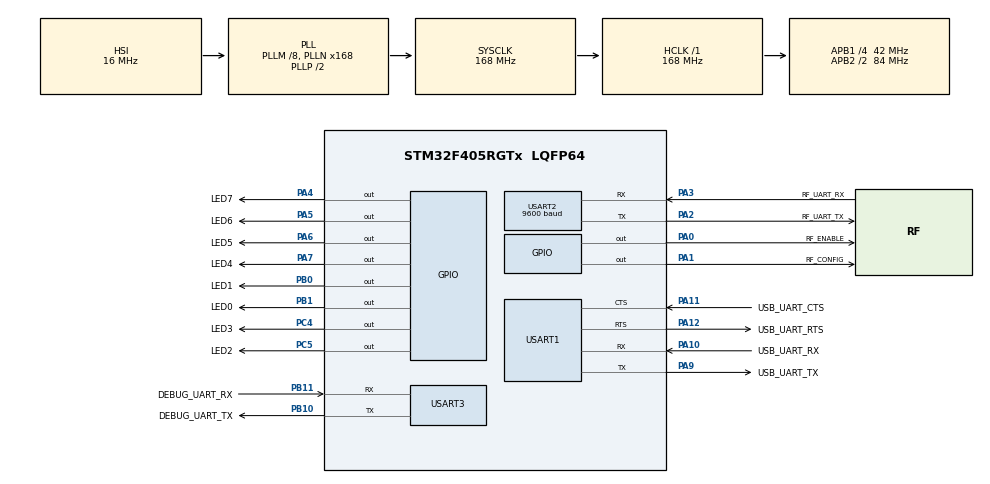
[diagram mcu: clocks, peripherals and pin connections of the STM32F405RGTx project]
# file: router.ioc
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Mcu.Family=STM32F4
Mcu.Name=STM32F405RGTx
Mcu.Package=LQFP64
NVIC.PriorityGroup=NVIC_PRIORITYGROUP_4
NVIC.USART1_IRQn=true\:0\:0\:false\:false\:true\:true
NVIC.USART2_IRQn=true\:0\:0\:false\:false\:true\:true
NVIC.USART3_IRQn=true\:0\:0\:false\:false\:true\:true
PA0-WKUP.GPIO_Label=RF_ENABLE
PA0-WKUP.Signal=GPIO_Output
PA1.GPIO_Label=RF_CONFIG
PA1.Signal=GPIO_Output
PA10.GPIO_Label=USB_UART_RX
PA10.Mode=Asynchronous
PA10.Signal=USART1_RX
PA11.GPIO_Label=USB_UART_CTS
PA11.Mode=CTS_RTS
PA11.Signal=USART1_CTS
PA12.GPIO_Label=USB_UART_RTS
PA12.Mode=CTS_RTS
PA12.Signal=USART1_RTS
PA13.Mode=Serial_Wire
PA13.Signal=SYS_JTMS-SWDIO
PA14.Mode=Serial_Wire
PA14.Signal=SYS_JTCK-SWCLK
PA2.GPIO_Label=RF_UART_TX
PA2.Mode=Asynchronous
PA2.Signal=USART2_TX
PA3.GPIO_Label=RF_UART_RX
PA3.Mode=Asynchronous
PA3.Signal=USART2_RX
PA4.GPIO_Label=LED7
PA4.Signal=GPIO_Output
PA5.GPIO_Label=LED6
PA5.Signal=GPIO_Output
PA6.GPIO_Label=LED5
PA6.Signal=GPIO_Output
PA7.GPIO_Label=LED4
PA7.Signal=GPIO_Output
PA9.GPIO_Label=USB_UART_TX
PA9.Mode=Asynchronous
PA9.Signal=USART1_TX
PB0.GPIO_Label=LED1
PB0.Signal=GPIO_Output
PB1.GPIO_Label=LED0
PB1.Signal=GPIO_Output
PB10.GPIO_Label=DEBUG_UART_TX
PB10.Mode=Asynchronous
PB10.Signal=USART3_TX
PB11.GPIO_Label=DEBUG_UART_RX
PB11.Mode=Asynchronous
PB11.Signal=USART3_RX
PC14-OSC32_IN.Mode=LSE-External-Oscillator
PC14-OSC32_IN.Signal=RCC_OSC32_IN
PC15-OSC32_OUT.Mode=LSE-External-Oscillator
PC15-OSC32_OUT.Signal=RCC_OSC32_OUT
PC4.GPIO_Label=LED3
PC4.Signal=GPIO_Output
PC5.GPIO_Label=LED2
PC5.Signal=GPIO_Output
ProjectManager.HeapSize=0x200
ProjectManager.StackSize=0x400
ProjectManager.TargetToolchain=Makefile
RCC.48MHZClocksFreq_Value=84000000
RCC.AHBFreq_Value=168000000
RCC.APB1CLKDivider=RCC_HCLK_DIV4
RCC.APB1Freq_Value=42000000
RCC.APB1TimFreq_Value=84000000
RCC.APB2CLKDivider=RCC_HCLK_DIV2
RCC.APB2Freq_Value=84000000
RCC.APB2TimFreq_Value=168000000
RCC.CortexFreq_Value=168000000
RCC.HCLKFreq_Value=168000000
RCC.HSE_VALUE=25000000
RCC.HSI_VALUE=16000000
RCC.PLLM=8
RCC.PLLN=168
RCC.RCC_RTC_Clock_Source=RCC_RTCCLKSOURCE_LSE
RCC.RCC_RTC_Clock_SourceVirtual=RCC_RTCCLKSOURCE_LSE
RCC.SYSCLKFreq_VALUE=168000000
RCC.SYSCLKSource=RCC_SYSCLKSOURCE_PLLCLK
RCC.VCOOutputFreq_Value=336000000
USART1.VirtualMode=VM_ASYNC
USART2.BaudRate=9600
USART2.VirtualMode=VM_ASYNC
USART3.VirtualMode=VM_ASYNC
VP_RTC_VS_RTC_Activate.Mode=RTC_Enabled
board=router

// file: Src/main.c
/**
 ******************************************************************************
 * @file           : main.c
 * @brief          : Main program body
 ******************************************************************************
 ** This notice applies to any and all portions of this file
 * that are not between comment pairs USER CODE BEGIN and
 * USER CODE END. Other portions of this file, whether
 * inserted by the user or by software development tools
 * are owned by their respective copyright owners.
 *
 * COPYRIGHT(c) 2018 STMicroelectronics
 *
 * Redistribution and use in source and binary forms, with or without modification,
 * are permitted provided that the following conditions are met:
 *   1. Redistributions of source code must retain the above copyright notice,
 *      this list of conditions and the following disclaimer.
 *   2. Redistributions in binary form must reproduce the above copyright notice,
 *      this list of conditions and the following disclaimer in the documentation
 *      and/or other materials provided with the distribution.
 *   3. Neither the name of STMicroelectronics nor the names of its contributors
 *      may be used to endorse or promote products derived from this software
 *      without specific prior written permission.
 *
 * THIS SOFTWARE IS PROVIDED BY THE COPYRIGHT HOLDERS AND CONTRIBUTORS "AS IS"
 * AND ANY EXPRESS OR IMPLIED WARRANTIES, INCLUDING, BUT NOT LIMITED TO, THE
 * IMPLIED WARRANTIES OF MERCHANTABILITY AND FITNESS FOR A PARTICULAR PURPOSE ARE
 * DISCLAIMED. IN NO EVENT SHALL THE COPYRIGHT HOLDER OR CONTRIBUTORS BE LIABLE
 * FOR ANY DIRECT, INDIRECT, INCIDENTAL, SPECIAL, EXEMPLARY, OR CONSEQUENTIAL
 * DAMAGES (INCLUDING, BUT NOT LIMITED TO, PROCUREMENT OF SUBSTITUTE GOODS OR
 * SERVICES; LOSS OF USE, DATA, OR PROFITS; OR BUSINESS INTERRUPTION) HOWEVER
 * CAUSED AND ON ANY THEORY OF LIABILITY, WHETHER IN CONTRACT, STRICT LIABILITY,
 * OR TORT (INCLUDING NEGLIGENCE OR OTHERWISE) ARISING IN ANY WAY OUT OF THE USE
 * OF THIS SOFTWARE, EVEN IF ADVISED OF THE POSSIBILITY OF SUCH DAMAGE.
 *
 ******************************************************************************
 */
#include "main.h"
#include "stm32f4xx_hal.h"

/* USER CODE BEGIN Includes */
#include "globals.hpp"
#include <string>
/* USER CODE END Includes */

RTC_HandleTypeDef hrtc;

UART_HandleTypeDef huart1;
UART_HandleTypeDef huart2;
UART_HandleTypeDef huart3;

/* USER CODE BEGIN PV */
/* Private variables ---------------------------------------------------------*/

/* USER CODE END PV */

void SystemClock_Config(void);
static void MX_GPIO_Init(void);
static void MX_USART1_UART_Init(void);
static void MX_USART2_UART_Init(void);
static void MX_USART3_UART_Init(void);
static void MX_RTC_Init(void);

/* USER CODE BEGIN PFP */
/* Private function prototypes -----------------------------------------------*/

/* USER CODE END PFP */

int main(void)
{

    /* MCU Configuration----------------------------------------------------------*/

    /* Reset of all peripherals, Initializes the Flash interface and the Systick. */
    HAL_Init();

    /* Configure the system clock */
    SystemClock_Config();

    /* Initialize all configured peripherals */
    MX_GPIO_Init();
    MX_USART1_UART_Init();
    MX_USART2_UART_Init();
    MX_USART3_UART_Init();
    MX_RTC_Init();
    /* USER CODE BEGIN 2 */
    global->usb   = new USB(&huart1);
    global->hmtrp = new HMTRP(&huart2, 57600, 0);
    global->radio_buffer_rx = new CircularBuffer;

    global->usb->tx("START\n");

    /* USER CODE END 2 */

    /* Infinite loop */
    while (1)
    {

        /* USER CODE BEGIN 3 */
        for (uint8_t i = 0; i < 10; i++)
        {
            HAL_Delay(500);
            //global->hmtrp->tx(i);
        }
    }
    /* USER CODE END 3 */
} /* main */

void SystemClock_Config(void)
{
    RCC_OscInitTypeDef RCC_OscInitStruct;
    RCC_ClkInitTypeDef RCC_ClkInitStruct;
    RCC_PeriphCLKInitTypeDef PeriphClkInitStruct;

    /**Configure the main internal regulator output voltage
     */
    __HAL_RCC_PWR_CLK_ENABLE();

    __HAL_PWR_VOLTAGESCALING_CONFIG(PWR_REGULATOR_VOLTAGE_SCALE1);

    /**Initializes the CPU, AHB and APB busses clocks
     */
    RCC_OscInitStruct.OscillatorType      = RCC_OSCILLATORTYPE_HSI | RCC_OSCILLATORTYPE_LSE;
    RCC_OscInitStruct.LSEState            = RCC_LSE_ON;
    RCC_OscInitStruct.HSIState            = RCC_HSI_ON;
    RCC_OscInitStruct.HSICalibrationValue = 16;
    RCC_OscInitStruct.PLL.PLLState        = RCC_PLL_ON;
    RCC_OscInitStruct.PLL.PLLSource       = RCC_PLLSOURCE_HSI;
    RCC_OscInitStruct.PLL.PLLM            = 8;
    RCC_OscInitStruct.PLL.PLLN            = 168;
    RCC_OscInitStruct.PLL.PLLP            = RCC_PLLP_DIV2;
    RCC_OscInitStruct.PLL.PLLQ            = 4;
    if (HAL_RCC_OscConfig(&RCC_OscInitStruct) != HAL_OK)
    {
        _Error_Handler(__FILE__, __LINE__);
    }

    /**Initializes the CPU, AHB and APB busses clocks
     */
    RCC_ClkInitStruct.ClockType = RCC_CLOCKTYPE_HCLK | RCC_CLOCKTYPE_SYSCLK
      | RCC_CLOCKTYPE_PCLK1 | RCC_CLOCKTYPE_PCLK2;
    RCC_ClkInitStruct.SYSCLKSource   = RCC_SYSCLKSOURCE_PLLCLK;
    RCC_ClkInitStruct.AHBCLKDivider  = RCC_SYSCLK_DIV1;
    RCC_ClkInitStruct.APB1CLKDivider = RCC_HCLK_DIV4;
    RCC_ClkInitStruct.APB2CLKDivider = RCC_HCLK_DIV2;

    if (HAL_RCC_ClockConfig(&RCC_ClkInitStruct, FLASH_LATENCY_5) != HAL_OK)
    {
        _Error_Handler(__FILE__, __LINE__);
    }

    PeriphClkInitStruct.PeriphClockSelection = RCC_PERIPHCLK_RTC;
    PeriphClkInitStruct.RTCClockSelection    = RCC_RTCCLKSOURCE_LSE;
    if (HAL_RCCEx_PeriphCLKConfig(&PeriphClkInitStruct) != HAL_OK)
    {
        _Error_Handler(__FILE__, __LINE__);
    }

    /**Configure the Systick interrupt time
     */
    HAL_SYSTICK_Config(HAL_RCC_GetHCLKFreq() / 1000);

    /**Configure the Systick
     */
    HAL_SYSTICK_CLKSourceConfig(SYSTICK_CLKSOURCE_HCLK);

    /* SysTick_IRQn interrupt configuration */
    HAL_NVIC_SetPriority(SysTick_IRQn, 0, 0);
} /* SystemClock_Config */

/* RTC init function */
static void MX_RTC_Init(void)
{
    /**Initialize RTC Only
     */
    hrtc.Instance            = RTC;
    hrtc.Init.HourFormat     = RTC_HOURFORMAT_24;
    hrtc.Init.AsynchPrediv   = 127;
    hrtc.Init.SynchPrediv    = 255;
    hrtc.Init.OutPut         = RTC_OUTPUT_DISABLE;
    hrtc.Init.OutPutPolarity = RTC_OUTPUT_POLARITY_HIGH;
    hrtc.Init.OutPutType     = RTC_OUTPUT_TYPE_OPENDRAIN;
    if (HAL_RTC_Init(&hrtc) != HAL_OK)
    {
        _Error_Handler(__FILE__, __LINE__);
    }
}

/* USART1 init function */
static void MX_USART1_UART_Init(void)
{
    huart1.Instance          = USART1;
    huart1.Init.BaudRate     = 115200;
    huart1.Init.WordLength   = UART_WORDLENGTH_8B;
    huart1.Init.StopBits     = UART_STOPBITS_1;
    huart1.Init.Parity       = UART_PARITY_NONE;
    huart1.Init.Mode         = UART_MODE_TX_RX;
    huart1.Init.HwFlowCtl    = UART_HWCONTROL_RTS_CTS;
    huart1.Init.OverSampling = UART_OVERSAMPLING_16;
    if (HAL_UART_Init(&huart1) != HAL_OK)
    {
        _Error_Handler(__FILE__, __LINE__);
    }
}

/* USART2 init function */
static void MX_USART2_UART_Init(void)
{
    huart2.Instance          = USART2;
    huart2.Init.BaudRate     = 9600;
    huart2.Init.WordLength   = UART_WORDLENGTH_8B;
    huart2.Init.StopBits     = UART_STOPBITS_1;
    huart2.Init.Parity       = UART_PARITY_NONE;
    huart2.Init.Mode         = UART_MODE_TX_RX;
    huart2.Init.HwFlowCtl    = UART_HWCONTROL_NONE;
    huart2.Init.OverSampling = UART_OVERSAMPLING_16;
    if (HAL_UART_Init(&huart2) != HAL_OK)
    {
        _Error_Handler(__FILE__, __LINE__);
    }
}

/* USART3 init function */
static void MX_USART3_UART_Init(void)
{
    huart3.Instance          = USART3;
    huart3.Init.BaudRate     = 115200;
    huart3.Init.WordLength   = UART_WORDLENGTH_8B;
    huart3.Init.StopBits     = UART_STOPBITS_1;
    huart3.Init.Parity       = UART_PARITY_NONE;
    huart3.Init.Mode         = UART_MODE_TX_RX;
    huart3.Init.HwFlowCtl    = UART_HWCONTROL_NONE;
    huart3.Init.OverSampling = UART_OVERSAMPLING_16;
    if (HAL_UART_Init(&huart3) != HAL_OK)
    {
        _Error_Handler(__FILE__, __LINE__);
    }
}

/** Configure pins as
 * Analog
 * Input
 * Output
 * EVENT_OUT
 * EXTI
 */
static void MX_GPIO_Init(void)
{
    GPIO_InitTypeDef GPIO_InitStruct;

    /* GPIO Ports Clock Enable */
    __HAL_RCC_GPIOC_CLK_ENABLE();
    __HAL_RCC_GPIOA_CLK_ENABLE();
    __HAL_RCC_GPIOB_CLK_ENABLE();

    /*Configure GPIO pin Output Level */
    HAL_GPIO_WritePin(GPIOA, RF_ENABLE_Pin | RF_CONFIG_Pin | LED7_Pin | LED6_Pin
      | LED5_Pin | LED4_Pin, GPIO_PIN_RESET);

    /*Configure GPIO pin Output Level */
    HAL_GPIO_WritePin(GPIOC, LED3_Pin | LED2_Pin, GPIO_PIN_RESET);

    /*Configure GPIO pin Output Level */
    HAL_GPIO_WritePin(GPIOB, LED1_Pin | LED0_Pin, GPIO_PIN_RESET);

    /*Configure GPIO pins : RF_ENABLE_Pin RF_CONFIG_Pin LED7_Pin LED6_Pin
     *                       LED5_Pin LED4_Pin */
    GPIO_InitStruct.Pin = RF_ENABLE_Pin | RF_CONFIG_Pin | LED7_Pin | LED6_Pin
      | LED5_Pin | LED4_Pin;
    GPIO_InitStruct.Mode  = GPIO_MODE_OUTPUT_PP;
    GPIO_InitStruct.Pull  = GPIO_NOPULL;
    GPIO_InitStruct.Speed = GPIO_SPEED_FREQ_LOW;
    HAL_GPIO_Init(GPIOA, &GPIO_InitStruct);

    /*Configure GPIO pins : LED3_Pin LED2_Pin */
    GPIO_InitStruct.Pin   = LED3_Pin | LED2_Pin;
    GPIO_InitStruct.Mode  = GPIO_MODE_OUTPUT_PP;
    GPIO_InitStruct.Pull  = GPIO_NOPULL;
    GPIO_InitStruct.Speed = GPIO_SPEED_FREQ_LOW;
    HAL_GPIO_Init(GPIOC, &GPIO_InitStruct);

    /*Configure GPIO pins : LED1_Pin LED0_Pin */
    GPIO_InitStruct.Pin   = LED1_Pin | LED0_Pin;
    GPIO_InitStruct.Mode  = GPIO_MODE_OUTPUT_PP;
    GPIO_InitStruct.Pull  = GPIO_NOPULL;
    GPIO_InitStruct.Speed = GPIO_SPEED_FREQ_LOW;
    HAL_GPIO_Init(GPIOB, &GPIO_InitStruct);
} /* MX_GPIO_Init */

void _Error_Handler(char *file, int line)
{
    /* USER CODE BEGIN Error_Handler_Debug */
    /* User can add his own implementation to report the HAL error return state */
    while (1)
    { }
    /* USER CODE END Error_Handler_Debug */
}

#ifdef  USE_FULL_ASSERT

/**
 * @brief  Reports the name of the source file and the source line number
 *         where the assert_param error has occurred.
 * @param  file: pointer to the source file name
 * @param  line: assert_param error line source number
 * @retval None
 */
void assert_failed(uint8_t *file, uint32_t line)
{
    /* USER CODE BEGIN 6 */

    /* User can add his own implementation to report the file name and line number,
     * tex: printf("Wrong parameters value: file %s on line %d\r\n", file, line) */
    /* USER CODE END 6 */
}

#endif /* USE_FULL_ASSERT */

/************************ (C) COPYRIGHT STMicroelectronics *****END OF FILE****/
